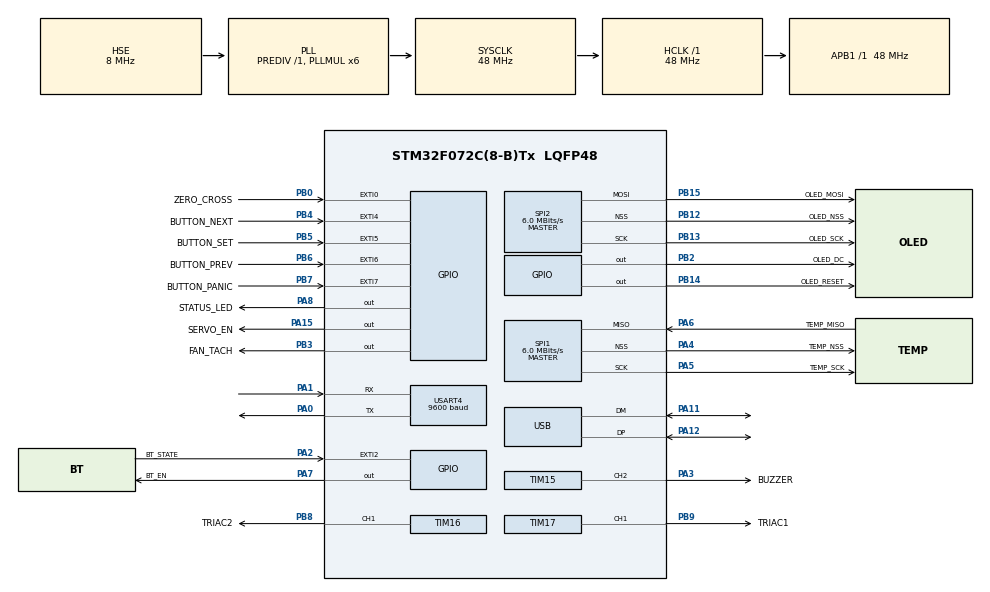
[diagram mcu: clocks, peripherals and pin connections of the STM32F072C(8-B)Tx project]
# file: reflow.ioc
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Mcu.Family=STM32F0
Mcu.Name=STM32F072C(8-B)Tx
Mcu.Package=LQFP48
NVIC.EXTI0_1_IRQn=true\:3\:0\:false\:false\:true\:true\:true
NVIC.EXTI2_3_IRQn=true\:3\:0\:false\:false\:true\:true\:true
NVIC.EXTI4_15_IRQn=true\:3\:0\:false\:false\:true\:true\:true
NVIC.TIM14_IRQn=true\:3\:0\:false\:false\:true\:true\:true
NVIC.TIM1_BRK_UP_TRG_COM_IRQn=true\:0\:0\:false\:false\:true\:false\:false
NVIC.TIM3_IRQn=true\:3\:0\:false\:false\:true\:true\:true
NVIC.TimeBase=TIM1_BRK_UP_TRG_COM_IRQn
NVIC.TimeBaseIP=TIM1
NVIC.USB_IRQn=true\:3\:0\:false\:false\:true\:true\:false
PA0.Mode=Asynchronous
PA0.Signal=USART4_TX
PA1.Mode=Asynchronous
PA1.Signal=USART4_RX
PA11.Mode=Device
PA11.Signal=USB_DM
PA12.Mode=Device
PA12.Signal=USB_DP
PA13.GPIO_Label=SWDIO
PA13.Mode=Serial_Wire
PA13.Signal=SYS_SWDIO
PA14.GPIO_Label=SWCLK
PA14.Mode=Serial_Wire
PA14.Signal=SYS_SWCLK
PA15.GPIO_Label=SERVO_EN
PA15.GPIO_PuPd=GPIO_PULLDOWN
PA15.GPIO_Speed=GPIO_SPEED_FREQ_LOW
PA15.PinState=GPIO_PIN_RESET
PA15.Signal=GPIO_Output
PA2.GPIO_Label=BT_STATE
PA2.GPIO_ModeDefaultEXTI=GPIO_MODE_IT_RISING_FALLING
PA2.GPIO_PuPd=GPIO_PULLUP
PA2.Signal=GPXTI2
PA3.GPIO_Label=BUZZER
PA3.Signal=S_TIM15_CH2
PA4.GPIO_Label=TEMP_NSS
PA4.Mode=NSS_Signal_Hard_Output
PA4.Signal=SPI1_NSS
PA5.GPIO_Label=TEMP_SCK
PA5.Mode=RX_Only_Simplex_Unidirect_Master
PA5.Signal=SPI1_SCK
PA6.GPIO_Label=TEMP_MISO
PA6.Mode=RX_Only_Simplex_Unidirect_Master
PA6.Signal=SPI1_MISO
PA7.GPIO_Label=BT_EN
PA7.GPIO_PuPd=GPIO_PULLDOWN
PA7.GPIO_Speed=GPIO_SPEED_FREQ_HIGH
PA7.PinState=GPIO_PIN_RESET
PA7.Signal=GPIO_Output
PA8.GPIO_Label=STATUS_LED
PA8.GPIO_ModeDefaultOutputPP=GPIO_MODE_OUTPUT_OD
PA8.GPIO_Speed=GPIO_SPEED_FREQ_HIGH
PA8.Signal=GPIO_Output
PB0.GPIO_Label=ZERO_CROSS
PB0.GPIO_ModeDefaultEXTI=GPIO_MODE_IT_FALLING
PB0.GPIO_PuPd=GPIO_PULLUP
PB0.Signal=GPXTI0
PB12.GPIO_Label=OLED_NSS
PB12.GPIO_PuPd=GPIO_PULLUP
PB12.Mode=NSS_Signal_Hard_Output
PB12.Signal=SPI2_NSS
PB13.GPIO_Label=OLED_SCK
PB13.GPIO_PuPd=GPIO_PULLUP
PB13.Mode=TX_Only_Simplex_Unidirect_Master
PB13.Signal=SPI2_SCK
PB14.GPIO_Label=OLED_RESET
PB14.GPIO_PuPd=GPIO_PULLUP
PB14.GPIO_Speed=GPIO_SPEED_FREQ_HIGH
PB14.PinState=GPIO_PIN_SET
PB14.Signal=GPIO_Output
PB15.GPIO_Label=OLED_MOSI
PB15.GPIO_PuPd=GPIO_PULLUP
PB15.Mode=TX_Only_Simplex_Unidirect_Master
PB15.Signal=SPI2_MOSI
PB2.GPIO_Label=OLED_DC
PB2.GPIO_PuPd=GPIO_PULLUP
PB2.GPIO_Speed=GPIO_SPEED_FREQ_HIGH
PB2.PinState=GPIO_PIN_SET
PB2.Signal=GPIO_Output
PB3.GPIO_Label=FAN_TACH
PB3.GPIO_PuPd=GPIO_PULLUP
PB3.PinState=GPIO_PIN_SET
PB3.Signal=GPIO_Output
PB4.GPIO_Label=BUTTON_NEXT
PB4.GPIO_ModeDefaultEXTI=GPIO_MODE_IT_FALLING
PB4.GPIO_PuPd=GPIO_PULLUP
PB4.Signal=GPXTI4
PB5.GPIO_Label=BUTTON_SET
PB5.GPIO_ModeDefaultEXTI=GPIO_MODE_IT_FALLING
PB5.GPIO_PuPd=GPIO_PULLUP
PB5.Signal=GPXTI5
PB6.GPIO_Label=BUTTON_PREV
PB6.GPIO_ModeDefaultEXTI=GPIO_MODE_IT_FALLING
PB6.GPIO_PuPd=GPIO_PULLUP
PB6.Signal=GPXTI6
PB7.GPIO_Label=BUTTON_PANIC
PB7.GPIO_ModeDefaultEXTI=GPIO_MODE_IT_FALLING
PB7.GPIO_PuPd=GPIO_PULLUP
PB7.Signal=GPXTI7
PB8.GPIO_Label=TRIAC2
PB8.GPIO_Speed=GPIO_SPEED_FREQ_HIGH
PB8.Signal=S_TIM16_CH1
PB9.GPIO_Label=TRIAC1
PB9.GPIO_Speed=GPIO_SPEED_FREQ_HIGH
PB9.Signal=S_TIM17_CH1
PF0-OSC_IN.Mode=HSE-External-Oscillator
PF0-OSC_IN.Signal=RCC_OSC_IN
PF1-OSC_OUT.Mode=HSE-External-Oscillator
PF1-OSC_OUT.Signal=RCC_OSC_OUT
ProjectManager.HeapSize=0x200
ProjectManager.StackSize=0x400
ProjectManager.TargetToolchain=Makefile
RCC.AHBFreq_Value=48000000
RCC.APB1Freq_Value=48000000
RCC.APB1TimFreq_Value=48000000
RCC.HCLKFreq_Value=48000000
RCC.PLLMUL=RCC_PLL_MUL6
RCC.PLLSourceVirtual=RCC_PLLSOURCE_HSE
RCC.SYSCLKFreq_VALUE=48000000
RCC.SYSCLKSource=RCC_SYSCLKSOURCE_PLLCLK
SH.S_TIM15_CH2.0=TIM15_CH2,PWM Generation2 CH2
SH.S_TIM16_CH1.0=TIM16_CH1,PWM Generation1 CH1
SH.S_TIM17_CH1.0=TIM17_CH1,PWM Generation1 CH1
SPI1.BaudRatePrescaler=SPI_BAUDRATEPRESCALER_8
SPI1.CLKPhase=SPI_PHASE_1EDGE
SPI1.CalculateBaudRate=6.0 MBits/s
SPI1.DataSize=SPI_DATASIZE_8BIT
SPI1.Direction=SPI_DIRECTION_2LINES_RXONLY
SPI1.FirstBit=SPI_FIRSTBIT_MSB
SPI1.Mode=SPI_MODE_MASTER
SPI1.NSSPMode=SPI_NSS_PULSE_DISABLE
SPI1.VirtualNSS=VM_NSSHARD
SPI1.VirtualType=VM_MASTER
SPI2.BaudRatePrescaler=SPI_BAUDRATEPRESCALER_8
SPI2.CLKPhase=SPI_PHASE_1EDGE
SPI2.CLKPolarity=SPI_POLARITY_LOW
SPI2.CalculateBaudRate=6.0 MBits/s
SPI2.DataSize=SPI_DATASIZE_8BIT
SPI2.Direction=SPI_DIRECTION_2LINES
SPI2.Mode=SPI_MODE_MASTER
SPI2.NSSPMode=SPI_NSS_PULSE_ENABLE
SPI2.VirtualNSS=VM_NSSHARD
SPI2.VirtualType=VM_MASTER
TIM14.AutoReloadPreload=TIM_AUTORELOAD_PRELOAD_ENABLE
TIM14.Channel=TIM_CHANNEL_1
TIM14.OCMode_1=TIM_OCMODE_TIMING
TIM14.OCPolarity_1=TIM_OCPOLARITY_LOW
TIM14.Period=1000-1
TIM14.Prescaler=48000-1
TIM14.Pulse=0
TIM15.Channel-PWM\ Generation2\ CH2=TIM_CHANNEL_2
TIM15.Period=40-1
TIM15.Prescaler=480-1
TIM15.Pulse-PWM\ Generation2\ CH2=20
TIM15.RepetitionCounter=100
TIM16.AutoReloadPreload=TIM_AUTORELOAD_PRELOAD_ENABLE
TIM16.AutomaticOutput=TIM_AUTOMATICOUTPUT_DISABLE
TIM16.BreakPolarity=TIM_BREAKPOLARITY_LOW
TIM16.BreakState=TIM_BREAK_DISABLE
TIM16.Channel=TIM_CHANNEL_1
TIM16.OCIdleState_1=TIM_OCIDLESTATE_RESET
TIM16.OCMode_PWM=TIM_OCMODE_PWM2
TIM16.OCPolarity_1=TIM_OCPOLARITY_LOW
TIM16.Period=1000-1
TIM16.Prescaler=8000-1
TIM16.Pulse=1000
TIM16.RepetitionCounter=0
TIM17.AutoReloadPreload=TIM_AUTORELOAD_PRELOAD_ENABLE
TIM17.BreakPolarity=TIM_BREAKPOLARITY_LOW
TIM17.Channel=TIM_CHANNEL_1
TIM17.OCIdleState_1=TIM_OCIDLESTATE_RESET
TIM17.OCMode_PWM=TIM_OCMODE_PWM2
TIM17.OCPolarity_1=TIM_OCPOLARITY_LOW
TIM17.Period=1000-1
TIM17.Prescaler=8000-1
TIM17.Pulse=1000
TIM17.RepetitionCounter=0
TIM2.AutoReloadPreload=TIM_AUTORELOAD_PRELOAD_ENABLE
TIM2.Period=999
TIM2.Prescaler=47
TIM2.TIM_MasterOutputTrigger=TIM_TRGO_RESET
TIM3.AutoReloadPreload=TIM_AUTORELOAD_PRELOAD_ENABLE
TIM3.Channel-Output\ Compare1\ No\ Output=TIM_CHANNEL_1
TIM3.ClearInputSource=TIM_CLEARINPUTSOURCE_OCREFCLR
TIM3.OCPolarity_1=TIM_OCPOLARITY_LOW
TIM3.Period=125-1
TIM3.Prescaler=48000-1
USART4.BaudRate=9600
USART4.VirtualMode-Asynchronous=VM_ASYNC
USB_DEVICE.CLASS_NAME_FS=CDC
USB_DEVICE.MANUFACTURER_STRING=Weyland Yutani Corp.
USB_DEVICE.PRODUCT_STRING_CDC_FS=Xenomorph Incubator
USB_DEVICE.VirtualMode=Cdc
USB_DEVICE.VirtualModeFS=Cdc_FS
VP_SYS_VS_tim1.Mode=TIM1
VP_TIM14_VS_ClockSourceINT.Mode=Enable_Timer
VP_TIM14_VS_no_output1.Mode=Output Compare1 No Output
VP_TIM15_VS_OPM.Mode=OPM_bit
VP_TIM16_VS_ClockSourceINT.Mode=Enable_Timer
VP_TIM17_VS_ClockSourceINT.Mode=Enable_Timer
VP_TIM2_VS_ClockSourceINT.Mode=Internal
VP_TIM3_VS_no_output1.Mode=Output Compare1 No Output
VP_USB_DEVICE_VS_USB_DEVICE_CDC_FS.Mode=CDC_FS
board=custom

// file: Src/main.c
/* USER CODE BEGIN Header */
/**
  * @brief  Function implementing the defaultTask thread.
  * @param  argument: Not used
  * @retval None
  */
/* USER CODE END Header */

#include "main.h"
#include "cmsis_os.h"
#include "usb_device.h"

/* USER CODE BEGIN Includes */
#include "app.h"
#include "timer.h"
/* USER CODE END Includes */

SPI_HandleTypeDef hspi1;
SPI_HandleTypeDef hspi2;

TIM_HandleTypeDef htim2;
TIM_HandleTypeDef htim3;
TIM_HandleTypeDef htim14;
TIM_HandleTypeDef htim15;
TIM_HandleTypeDef htim16;
TIM_HandleTypeDef htim17;

UART_HandleTypeDef huart4;

osThreadId defaultTaskHandle;
/* USER CODE BEGIN PV */
/* Private variables ---------------------------------------------------------*/

/* USER CODE END PV */

void SystemClock_Config(void);
static void MX_GPIO_Init(void);
static void MX_SPI1_Init(void);
static void MX_SPI2_Init(void);
static void MX_USART4_UART_Init(void);
static void MX_TIM14_Init(void);
static void MX_TIM2_Init(void);
static void MX_TIM15_Init(void);
static void MX_TIM16_Init(void);
static void MX_TIM17_Init(void);
static void MX_TIM3_Init(void);
void StartDefaultTask(void const * argument);

/* USER CODE BEGIN PFP */
/* Private function prototypes -----------------------------------------------*/

/* USER CODE END PFP */

int main(void)
{

  /* MCU Configuration--------------------------------------------------------*/

  /* Reset of all peripherals, Initializes the Flash interface and the Systick. */
  HAL_Init();

  /* Configure the system clock */
  SystemClock_Config();

  /* Initialize all configured peripherals */
  MX_GPIO_Init();
  MX_SPI1_Init();
  MX_SPI2_Init();
  MX_USART4_UART_Init();
  MX_TIM14_Init();
  MX_TIM2_Init();
  MX_TIM15_Init();
  MX_TIM16_Init();
  MX_TIM17_Init();
  MX_TIM3_Init();
  /* USER CODE BEGIN 2 */

  app_init();

  /* USER CODE END 2 */

  /* Create the thread(s) */
  /* definition and creation of defaultTask */
  osThreadDef(defaultTask, StartDefaultTask, osPriorityNormal, 0, 128);
  defaultTaskHandle = osThreadCreate(osThread(defaultTask), NULL);

  /* Start scheduler */
  osKernelStart();

  /* We should never get here as control is now taken by the scheduler */

  /* Infinite loop */

}

void SystemClock_Config(void)
{
  RCC_OscInitTypeDef RCC_OscInitStruct = {0};
  RCC_ClkInitTypeDef RCC_ClkInitStruct = {0};
  RCC_PeriphCLKInitTypeDef PeriphClkInit = {0};

  /**Initializes the CPU, AHB and APB busses clocks
  */
  RCC_OscInitStruct.OscillatorType = RCC_OSCILLATORTYPE_HSI48|RCC_OSCILLATORTYPE_HSE;
  RCC_OscInitStruct.HSEState = RCC_HSE_ON;
  RCC_OscInitStruct.HSI48State = RCC_HSI48_ON;
  RCC_OscInitStruct.PLL.PLLState = RCC_PLL_ON;
  RCC_OscInitStruct.PLL.PLLSource = RCC_PLLSOURCE_HSE;
  RCC_OscInitStruct.PLL.PLLMUL = RCC_PLL_MUL6;
  RCC_OscInitStruct.PLL.PREDIV = RCC_PREDIV_DIV1;
  if (HAL_RCC_OscConfig(&RCC_OscInitStruct) != HAL_OK)
  {
    Error_Handler();
  }
  /**Initializes the CPU, AHB and APB busses clocks
  */
  RCC_ClkInitStruct.ClockType = RCC_CLOCKTYPE_HCLK|RCC_CLOCKTYPE_SYSCLK
                              |RCC_CLOCKTYPE_PCLK1;
  RCC_ClkInitStruct.SYSCLKSource = RCC_SYSCLKSOURCE_PLLCLK;
  RCC_ClkInitStruct.AHBCLKDivider = RCC_SYSCLK_DIV1;
  RCC_ClkInitStruct.APB1CLKDivider = RCC_HCLK_DIV1;

  if (HAL_RCC_ClockConfig(&RCC_ClkInitStruct, FLASH_LATENCY_1) != HAL_OK)
  {
    Error_Handler();
  }
  PeriphClkInit.PeriphClockSelection = RCC_PERIPHCLK_USB;
  PeriphClkInit.UsbClockSelection = RCC_USBCLKSOURCE_HSI48;

  if (HAL_RCCEx_PeriphCLKConfig(&PeriphClkInit) != HAL_OK)
  {
    Error_Handler();
  }
}

static void MX_SPI1_Init(void)
{

  /* SPI1 parameter configuration*/
  hspi1.Instance = SPI1;
  hspi1.Init.Mode = SPI_MODE_MASTER;
  hspi1.Init.Direction = SPI_DIRECTION_2LINES_RXONLY;
  hspi1.Init.DataSize = SPI_DATASIZE_8BIT;
  hspi1.Init.CLKPolarity = SPI_POLARITY_LOW;
  hspi1.Init.CLKPhase = SPI_PHASE_1EDGE;
  hspi1.Init.NSS = SPI_NSS_HARD_OUTPUT;
  hspi1.Init.BaudRatePrescaler = SPI_BAUDRATEPRESCALER_8;
  hspi1.Init.FirstBit = SPI_FIRSTBIT_MSB;
  hspi1.Init.TIMode = SPI_TIMODE_DISABLE;
  hspi1.Init.CRCCalculation = SPI_CRCCALCULATION_DISABLE;
  hspi1.Init.CRCPolynomial = 7;
  hspi1.Init.CRCLength = SPI_CRC_LENGTH_DATASIZE;
  hspi1.Init.NSSPMode = SPI_NSS_PULSE_DISABLE;
  if (HAL_SPI_Init(&hspi1) != HAL_OK)
  {
    Error_Handler();
  }

}

static void MX_SPI2_Init(void)
{

  /* SPI2 parameter configuration*/
  hspi2.Instance = SPI2;
  hspi2.Init.Mode = SPI_MODE_MASTER;
  hspi2.Init.Direction = SPI_DIRECTION_2LINES;
  hspi2.Init.DataSize = SPI_DATASIZE_8BIT;
  hspi2.Init.CLKPolarity = SPI_POLARITY_LOW;
  hspi2.Init.CLKPhase = SPI_PHASE_1EDGE;
  hspi2.Init.NSS = SPI_NSS_HARD_OUTPUT;
  hspi2.Init.BaudRatePrescaler = SPI_BAUDRATEPRESCALER_8;
  hspi2.Init.FirstBit = SPI_FIRSTBIT_MSB;
  hspi2.Init.TIMode = SPI_TIMODE_DISABLE;
  hspi2.Init.CRCCalculation = SPI_CRCCALCULATION_DISABLE;
  hspi2.Init.CRCPolynomial = 7;
  hspi2.Init.CRCLength = SPI_CRC_LENGTH_DATASIZE;
  hspi2.Init.NSSPMode = SPI_NSS_PULSE_ENABLE;
  if (HAL_SPI_Init(&hspi2) != HAL_OK)
  {
    Error_Handler();
  }

}

static void MX_TIM2_Init(void)
{

  TIM_ClockConfigTypeDef sClockSourceConfig = {0};
  TIM_MasterConfigTypeDef sMasterConfig = {0};

  htim2.Instance = TIM2;
  htim2.Init.Prescaler = 47;
  htim2.Init.CounterMode = TIM_COUNTERMODE_UP;
  htim2.Init.Period = 999;
  htim2.Init.ClockDivision = TIM_CLOCKDIVISION_DIV1;
  htim2.Init.AutoReloadPreload = TIM_AUTORELOAD_PRELOAD_ENABLE;
  if (HAL_TIM_Base_Init(&htim2) != HAL_OK)
  {
    Error_Handler();
  }
  sClockSourceConfig.ClockSource = TIM_CLOCKSOURCE_INTERNAL;
  if (HAL_TIM_ConfigClockSource(&htim2, &sClockSourceConfig) != HAL_OK)
  {
    Error_Handler();
  }
  sMasterConfig.MasterOutputTrigger = TIM_TRGO_RESET;
  sMasterConfig.MasterSlaveMode = TIM_MASTERSLAVEMODE_DISABLE;
  if (HAL_TIMEx_MasterConfigSynchronization(&htim2, &sMasterConfig) != HAL_OK)
  {
    Error_Handler();
  }

}

static void MX_TIM3_Init(void)
{

  TIM_MasterConfigTypeDef sMasterConfig = {0};
  TIM_OC_InitTypeDef sConfigOC = {0};

  htim3.Instance = TIM3;
  htim3.Init.Prescaler = 48000-1;
  htim3.Init.CounterMode = TIM_COUNTERMODE_UP;
  htim3.Init.Period = 125-1;
  htim3.Init.ClockDivision = TIM_CLOCKDIVISION_DIV1;
  htim3.Init.AutoReloadPreload = TIM_AUTORELOAD_PRELOAD_ENABLE;
  if (HAL_TIM_OC_Init(&htim3) != HAL_OK)
  {
    Error_Handler();
  }
  sMasterConfig.MasterOutputTrigger = TIM_TRGO_RESET;
  sMasterConfig.MasterSlaveMode = TIM_MASTERSLAVEMODE_DISABLE;
  if (HAL_TIMEx_MasterConfigSynchronization(&htim3, &sMasterConfig) != HAL_OK)
  {
    Error_Handler();
  }
  sConfigOC.OCMode = TIM_OCMODE_TIMING;
  sConfigOC.Pulse = 0;
  sConfigOC.OCPolarity = TIM_OCPOLARITY_LOW;
  sConfigOC.OCFastMode = TIM_OCFAST_DISABLE;
  if (HAL_TIM_OC_ConfigChannel(&htim3, &sConfigOC, TIM_CHANNEL_1) != HAL_OK)
  {
    Error_Handler();
  }

}

static void MX_TIM14_Init(void)
{

  TIM_OC_InitTypeDef sConfigOC = {0};

  htim14.Instance = TIM14;
  htim14.Init.Prescaler = 48000-1;
  htim14.Init.CounterMode = TIM_COUNTERMODE_UP;
  htim14.Init.Period = 1000-1;
  htim14.Init.ClockDivision = TIM_CLOCKDIVISION_DIV1;
  htim14.Init.AutoReloadPreload = TIM_AUTORELOAD_PRELOAD_ENABLE;
  if (HAL_TIM_Base_Init(&htim14) != HAL_OK)
  {
    Error_Handler();
  }
  if (HAL_TIM_OC_Init(&htim14) != HAL_OK)
  {
    Error_Handler();
  }
  sConfigOC.OCMode = TIM_OCMODE_TIMING;
  sConfigOC.Pulse = 0;
  sConfigOC.OCPolarity = TIM_OCPOLARITY_LOW;
  sConfigOC.OCFastMode = TIM_OCFAST_DISABLE;
  if (HAL_TIM_OC_ConfigChannel(&htim14, &sConfigOC, TIM_CHANNEL_1) != HAL_OK)
  {
    Error_Handler();
  }

}

static void MX_TIM15_Init(void)
{

  TIM_MasterConfigTypeDef sMasterConfig = {0};
  TIM_OC_InitTypeDef sConfigOC = {0};
  TIM_BreakDeadTimeConfigTypeDef sBreakDeadTimeConfig = {0};

  htim15.Instance = TIM15;
  htim15.Init.Prescaler = 480-1;
  htim15.Init.CounterMode = TIM_COUNTERMODE_UP;
  htim15.Init.Period = 40-1;
  htim15.Init.ClockDivision = TIM_CLOCKDIVISION_DIV1;
  htim15.Init.RepetitionCounter = 100;
  htim15.Init.AutoReloadPreload = TIM_AUTORELOAD_PRELOAD_DISABLE;
  if (HAL_TIM_PWM_Init(&htim15) != HAL_OK)
  {
    Error_Handler();
  }
  if (HAL_TIM_OnePulse_Init(&htim15, TIM_OPMODE_SINGLE) != HAL_OK)
  {
    Error_Handler();
  }
  sMasterConfig.MasterOutputTrigger = TIM_TRGO_RESET;
  sMasterConfig.MasterSlaveMode = TIM_MASTERSLAVEMODE_DISABLE;
  if (HAL_TIMEx_MasterConfigSynchronization(&htim15, &sMasterConfig) != HAL_OK)
  {
    Error_Handler();
  }
  sConfigOC.OCMode = TIM_OCMODE_PWM1;
  sConfigOC.Pulse = 20;
  sConfigOC.OCPolarity = TIM_OCPOLARITY_HIGH;
  sConfigOC.OCNPolarity = TIM_OCNPOLARITY_HIGH;
  sConfigOC.OCFastMode = TIM_OCFAST_DISABLE;
  sConfigOC.OCIdleState = TIM_OCIDLESTATE_RESET;
  sConfigOC.OCNIdleState = TIM_OCNIDLESTATE_RESET;
  if (HAL_TIM_PWM_ConfigChannel(&htim15, &sConfigOC, TIM_CHANNEL_2) != HAL_OK)
  {
    Error_Handler();
  }
  sBreakDeadTimeConfig.OffStateRunMode = TIM_OSSR_DISABLE;
  sBreakDeadTimeConfig.OffStateIDLEMode = TIM_OSSI_DISABLE;
  sBreakDeadTimeConfig.LockLevel = TIM_LOCKLEVEL_OFF;
  sBreakDeadTimeConfig.DeadTime = 0;
  sBreakDeadTimeConfig.BreakState = TIM_BREAK_DISABLE;
  sBreakDeadTimeConfig.BreakPolarity = TIM_BREAKPOLARITY_HIGH;
  sBreakDeadTimeConfig.AutomaticOutput = TIM_AUTOMATICOUTPUT_DISABLE;
  if (HAL_TIMEx_ConfigBreakDeadTime(&htim15, &sBreakDeadTimeConfig) != HAL_OK)
  {
    Error_Handler();
  }
  HAL_TIM_MspPostInit(&htim15);

}

static void MX_TIM16_Init(void)
{

  TIM_OC_InitTypeDef sConfigOC = {0};
  TIM_BreakDeadTimeConfigTypeDef sBreakDeadTimeConfig = {0};

  htim16.Instance = TIM16;
  htim16.Init.Prescaler = 8000-1;
  htim16.Init.CounterMode = TIM_COUNTERMODE_UP;
  htim16.Init.Period = 1000-1;
  htim16.Init.ClockDivision = TIM_CLOCKDIVISION_DIV1;
  htim16.Init.RepetitionCounter = 0;
  htim16.Init.AutoReloadPreload = TIM_AUTORELOAD_PRELOAD_ENABLE;
  if (HAL_TIM_Base_Init(&htim16) != HAL_OK)
  {
    Error_Handler();
  }
  if (HAL_TIM_PWM_Init(&htim16) != HAL_OK)
  {
    Error_Handler();
  }
  sConfigOC.OCMode = TIM_OCMODE_PWM2;
  sConfigOC.Pulse = 1000;
  sConfigOC.OCPolarity = TIM_OCPOLARITY_LOW;
  sConfigOC.OCNPolarity = TIM_OCNPOLARITY_HIGH;
  sConfigOC.OCFastMode = TIM_OCFAST_DISABLE;
  sConfigOC.OCIdleState = TIM_OCIDLESTATE_RESET;
  sConfigOC.OCNIdleState = TIM_OCNIDLESTATE_RESET;
  if (HAL_TIM_PWM_ConfigChannel(&htim16, &sConfigOC, TIM_CHANNEL_1) != HAL_OK)
  {
    Error_Handler();
  }
  sBreakDeadTimeConfig.OffStateRunMode = TIM_OSSR_DISABLE;
  sBreakDeadTimeConfig.OffStateIDLEMode = TIM_OSSI_DISABLE;
  sBreakDeadTimeConfig.LockLevel = TIM_LOCKLEVEL_OFF;
  sBreakDeadTimeConfig.DeadTime = 0;
  sBreakDeadTimeConfig.BreakState = TIM_BREAK_DISABLE;
  sBreakDeadTimeConfig.BreakPolarity = TIM_BREAKPOLARITY_LOW;
  sBreakDeadTimeConfig.AutomaticOutput = TIM_AUTOMATICOUTPUT_DISABLE;
  if (HAL_TIMEx_ConfigBreakDeadTime(&htim16, &sBreakDeadTimeConfig) != HAL_OK)
  {
    Error_Handler();
  }
  HAL_TIM_MspPostInit(&htim16);

}

static void MX_TIM17_Init(void)
{

  TIM_OC_InitTypeDef sConfigOC = {0};
  TIM_BreakDeadTimeConfigTypeDef sBreakDeadTimeConfig = {0};

  htim17.Instance = TIM17;
  htim17.Init.Prescaler = 8000-1;
  htim17.Init.CounterMode = TIM_COUNTERMODE_UP;
  htim17.Init.Period = 1000-1;
  htim17.Init.ClockDivision = TIM_CLOCKDIVISION_DIV1;
  htim17.Init.RepetitionCounter = 0;
  htim17.Init.AutoReloadPreload = TIM_AUTORELOAD_PRELOAD_ENABLE;
  if (HAL_TIM_Base_Init(&htim17) != HAL_OK)
  {
    Error_Handler();
  }
  if (HAL_TIM_PWM_Init(&htim17) != HAL_OK)
  {
    Error_Handler();
  }
  sConfigOC.OCMode = TIM_OCMODE_PWM2;
  sConfigOC.Pulse = 1000;
  sConfigOC.OCPolarity = TIM_OCPOLARITY_LOW;
  sConfigOC.OCNPolarity = TIM_OCNPOLARITY_HIGH;
  sConfigOC.OCFastMode = TIM_OCFAST_DISABLE;
  sConfigOC.OCIdleState = TIM_OCIDLESTATE_RESET;
  sConfigOC.OCNIdleState = TIM_OCNIDLESTATE_RESET;
  if (HAL_TIM_PWM_ConfigChannel(&htim17, &sConfigOC, TIM_CHANNEL_1) != HAL_OK)
  {
    Error_Handler();
  }
  sBreakDeadTimeConfig.OffStateRunMode = TIM_OSSR_DISABLE;
  sBreakDeadTimeConfig.OffStateIDLEMode = TIM_OSSI_DISABLE;
  sBreakDeadTimeConfig.LockLevel = TIM_LOCKLEVEL_OFF;
  sBreakDeadTimeConfig.DeadTime = 0;
  sBreakDeadTimeConfig.BreakState = TIM_BREAK_DISABLE;
  sBreakDeadTimeConfig.BreakPolarity = TIM_BREAKPOLARITY_LOW;
  sBreakDeadTimeConfig.AutomaticOutput = TIM_AUTOMATICOUTPUT_DISABLE;
  if (HAL_TIMEx_ConfigBreakDeadTime(&htim17, &sBreakDeadTimeConfig) != HAL_OK)
  {
    Error_Handler();
  }
  HAL_TIM_MspPostInit(&htim17);

}

static void MX_USART4_UART_Init(void)
{

  huart4.Instance = USART4;
  huart4.Init.BaudRate = 9600;
  huart4.Init.WordLength = UART_WORDLENGTH_8B;
  huart4.Init.StopBits = UART_STOPBITS_1;
  huart4.Init.Parity = UART_PARITY_NONE;
  huart4.Init.Mode = UART_MODE_TX_RX;
  huart4.Init.HwFlowCtl = UART_HWCONTROL_NONE;
  huart4.Init.OverSampling = UART_OVERSAMPLING_16;
  huart4.Init.OneBitSampling = UART_ONE_BIT_SAMPLE_DISABLE;
  huart4.AdvancedInit.AdvFeatureInit = UART_ADVFEATURE_NO_INIT;
  if (HAL_UART_Init(&huart4) != HAL_OK)
  {
    Error_Handler();
  }

}

static void MX_GPIO_Init(void)
{
  GPIO_InitTypeDef GPIO_InitStruct = {0};

  /* GPIO Ports Clock Enable */
  __HAL_RCC_GPIOC_CLK_ENABLE();
  __HAL_RCC_GPIOF_CLK_ENABLE();
  __HAL_RCC_GPIOA_CLK_ENABLE();
  __HAL_RCC_GPIOB_CLK_ENABLE();

  /*Configure GPIO pin Output Level */
  HAL_GPIO_WritePin(GPIOA, BT_EN_Pin|STATUS_LED_Pin|SERVO_EN_Pin, GPIO_PIN_RESET);

  /*Configure GPIO pin Output Level */
  HAL_GPIO_WritePin(GPIOB, OLED_DC_Pin|OLED_RESET_Pin|FAN_TACH_Pin, GPIO_PIN_SET);

  /*Configure GPIO pins : PC13 PC14 PC15 */
  GPIO_InitStruct.Pin = GPIO_PIN_13|GPIO_PIN_14|GPIO_PIN_15;
  GPIO_InitStruct.Mode = GPIO_MODE_ANALOG;
  GPIO_InitStruct.Pull = GPIO_NOPULL;
  HAL_GPIO_Init(GPIOC, &GPIO_InitStruct);

  /*Configure GPIO pin : BT_STATE_Pin */
  GPIO_InitStruct.Pin = BT_STATE_Pin;
  GPIO_InitStruct.Mode = GPIO_MODE_IT_RISING_FALLING;
  GPIO_InitStruct.Pull = GPIO_PULLUP;
  HAL_GPIO_Init(BT_STATE_GPIO_Port, &GPIO_InitStruct);

  /*Configure GPIO pin : BT_EN_Pin */
  GPIO_InitStruct.Pin = BT_EN_Pin;
  GPIO_InitStruct.Mode = GPIO_MODE_OUTPUT_PP;
  GPIO_InitStruct.Pull = GPIO_PULLDOWN;
  GPIO_InitStruct.Speed = GPIO_SPEED_FREQ_HIGH;
  HAL_GPIO_Init(BT_EN_GPIO_Port, &GPIO_InitStruct);

  /*Configure GPIO pins : ZERO_CROSS_Pin BUTTON_NEXT_Pin BUTTON_SET_Pin BUTTON_PREV_Pin
                           BUTTON_PANIC_Pin */
  GPIO_InitStruct.Pin = ZERO_CROSS_Pin|BUTTON_NEXT_Pin|BUTTON_SET_Pin|BUTTON_PREV_Pin
                          |BUTTON_PANIC_Pin;
  GPIO_InitStruct.Mode = GPIO_MODE_IT_FALLING;
  GPIO_InitStruct.Pull = GPIO_PULLUP;
  HAL_GPIO_Init(GPIOB, &GPIO_InitStruct);

  /*Configure GPIO pins : PB1 PB10 PB11 */
  GPIO_InitStruct.Pin = GPIO_PIN_1|GPIO_PIN_10|GPIO_PIN_11;
  GPIO_InitStruct.Mode = GPIO_MODE_ANALOG;
  GPIO_InitStruct.Pull = GPIO_NOPULL;
  HAL_GPIO_Init(GPIOB, &GPIO_InitStruct);

  /*Configure GPIO pins : OLED_DC_Pin OLED_RESET_Pin */
  GPIO_InitStruct.Pin = OLED_DC_Pin|OLED_RESET_Pin;
  GPIO_InitStruct.Mode = GPIO_MODE_OUTPUT_PP;
  GPIO_InitStruct.Pull = GPIO_PULLUP;
  GPIO_InitStruct.Speed = GPIO_SPEED_FREQ_HIGH;
  HAL_GPIO_Init(GPIOB, &GPIO_InitStruct);

  /*Configure GPIO pin : STATUS_LED_Pin */
  GPIO_InitStruct.Pin = STATUS_LED_Pin;
  GPIO_InitStruct.Mode = GPIO_MODE_OUTPUT_OD;
  GPIO_InitStruct.Pull = GPIO_NOPULL;
  GPIO_InitStruct.Speed = GPIO_SPEED_FREQ_HIGH;
  HAL_GPIO_Init(STATUS_LED_GPIO_Port, &GPIO_InitStruct);

  /*Configure GPIO pins : PA9 PA10 */
  GPIO_InitStruct.Pin = GPIO_PIN_9|GPIO_PIN_10;
  GPIO_InitStruct.Mode = GPIO_MODE_ANALOG;
  GPIO_InitStruct.Pull = GPIO_NOPULL;
  HAL_GPIO_Init(GPIOA, &GPIO_InitStruct);

  /*Configure GPIO pin : SERVO_EN_Pin */
  GPIO_InitStruct.Pin = SERVO_EN_Pin;
  GPIO_InitStruct.Mode = GPIO_MODE_OUTPUT_PP;
  GPIO_InitStruct.Pull = GPIO_PULLDOWN;
  GPIO_InitStruct.Speed = GPIO_SPEED_FREQ_LOW;
  HAL_GPIO_Init(SERVO_EN_GPIO_Port, &GPIO_InitStruct);

  /*Configure GPIO pin : FAN_TACH_Pin */
  GPIO_InitStruct.Pin = FAN_TACH_Pin;
  GPIO_InitStruct.Mode = GPIO_MODE_OUTPUT_PP;
  GPIO_InitStruct.Pull = GPIO_PULLUP;
  GPIO_InitStruct.Speed = GPIO_SPEED_FREQ_LOW;
  HAL_GPIO_Init(FAN_TACH_GPIO_Port, &GPIO_InitStruct);

  /* EXTI interrupt init*/
  HAL_NVIC_SetPriority(EXTI0_1_IRQn, 3, 0);
  HAL_NVIC_EnableIRQ(EXTI0_1_IRQn);

  HAL_NVIC_SetPriority(EXTI2_3_IRQn, 3, 0);
  HAL_NVIC_EnableIRQ(EXTI2_3_IRQn);

  HAL_NVIC_SetPriority(EXTI4_15_IRQn, 3, 0);
  HAL_NVIC_EnableIRQ(EXTI4_15_IRQn);

}

void StartDefaultTask(void const * argument)
{
  /* init code for USB_DEVICE */
  MX_USB_DEVICE_Init();

  /* USER CODE BEGIN 5 */
  /* Infinite loop */
  (void) argument;

  for(;;)
  {
    osDelay(1);
  }
  /* USER CODE END 5 */
}

void HAL_TIM_PeriodElapsedCallback(TIM_HandleTypeDef *htim)
{
  if (htim->Instance == TIM1) {
    HAL_IncTick();
  }
  /* USER CODE BEGIN Callback 1 */
  if (htim->Instance == TIM14) {
      timer_tick_1hz();
  }

  if (htim->Instance == TIM3) {
      timer_tick_speaker();
  }
  /* USER CODE END Callback 1 */
}

void Error_Handler(void)
{
  while(1)
  {
  }
}

/************************ (C) COPYRIGHT STMicroelectronics *****END OF FILE****/
